# LPC122x register map
File version: 2
Registers are 32-bit, read-write, reset 0x0 unless marked. A register's access mark holds for its fields unless they carry their own. Offsets are from the block's base; [hi:lo] are bit positions; {n}, {i} and the like mark numbered series; 'fields as' and 'values as' point back to an identical list.

## UART0 — Product name title=UM10441 Chapter title=LPC122x UART0 with modem control Modification date=2/2/2011 Major revision=0 Minor revision=17
Base 0x40008000
0x00 RBR ro read-modifies — Receiver Buffer Register. Contains the next received character to be read. (DLAB=0)
  [7:0] RBR — The UART Receiver Buffer Register contains the oldest received byte in the UART RX FIFO.
0x00 THR wo (alternate view of RBR) — Transmit Holding Register. The next character to be transmitted is written here. (DLAB=0)
  [7:0] THR — Writing to the UART Transmit Holding Register causes the data to be stored in the UART transmit FIFO. The byte will be sent when it reaches the bottom of the FIFO and the transmitter is available.
0x00 DLL reset 0x1 (alternate view of RBR) — Divisor Latch LSB. Least significant byte of the baud rate divisor value. The full divisor is used to generate a baud rate from the fractional rate divider. (DLAB = 1)
  [7:0] DLLSB — The UART Divisor Latch LSB Register, along with the DLM register, determines the baud rate of the UART.
0x04 DLM — Divisor Latch MSB. Most significant byte of the baud rate divisor value. The full divisor is used to generate a baud rate from the fractional rate divider. (DLAB = 1)
  [7:0] DLMSB — The UART Divisor Latch MSB Register, along with the DLL register, determines the baud rate of the UART.
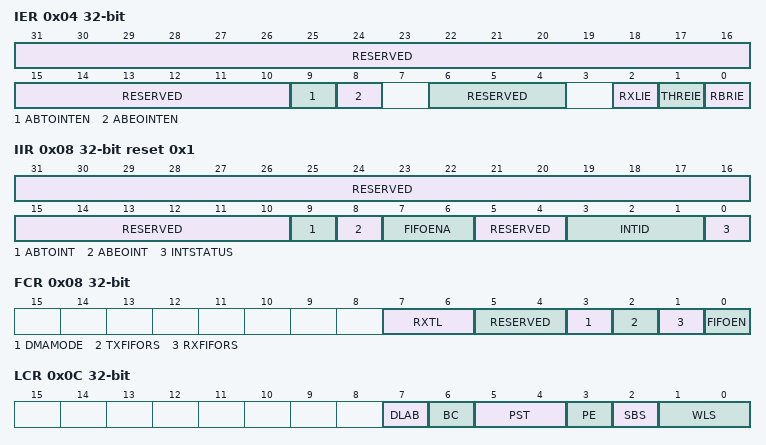
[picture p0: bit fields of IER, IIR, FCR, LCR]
0x04 IER (alternate view of DLM) — Interrupt Enable Register. Contains individual interrupt enable bits for the 7 potential UART interrupts. (DLAB=0)
  [31:10] RESERVED — Reserved, user software should not write ones to reserved bits. The value read from a reserved bit is not defined.
  [9] ABTOINTEN — Enables the auto-baud time-out interrupt.
    0=DISABLE_AUTO_BAUD_TI (Disable auto-baud time-out Interrupt.); 1=ENABLE_AUTO_BAUD_TIM (Enable auto-baud time-out Interrupt.)
  [8] ABEOINTEN — Enables the end of auto-baud interrupt.
    0=DISABLE_END_OF_AUTO_ (Disable end of auto-baud Interrupt.); 1=ENABLE_END_OF_AUTO_B (Enable end of auto-baud Interrupt.)
  [6:4] RESERVED — Reserved, user software should not write ones to reserved bits. The value read from a reserved bit is not defined.
  [2] RXLIE — RX Line Interrupt Enable. Enables the UART RX line status interrupts. The status of this interrupt can be read from LSR[4:1].
    0=DISABLE_THE_RX_LINE_ (Disable the RX line status interrupts.); 1=ENABLE_THE_RX_LINE_S (Enable the RX line status interrupts.)
  [1] THREIE — THRE Interrupt Enable. Enables the THRE interrupt for UART. The status of this interrupt can be read from LSR[5].
    0=DISABLE_THE_THRE_INT (Disable the THRE interrupts.); 1=ENABLE_THE_THRE_INTE (Enable the THRE interrupts.)
  [0] RBRIE — RBR Interrupt Enable. Enables the Receive Data Available interrupt for UART. It also controls the Character Receive Time-out interrupt.
    0=DISABLE_THE_RDA_INTE (Disable the RDA interrupts.); 1=ENABLE_THE_RDA_INTER (Enable the RDA interrupts.)
0x08 IIR ro reset 0x1 — Interrupt ID Register. Identifies which interrupt(s) are pending.
  [31:10] RESERVED — Reserved, user software should not write ones to reserved bits. The value read from a reserved bit is not defined.
  [9] ABTOINT — Auto-baud time-out interrupt. True if auto-baud has timed out and interrupt is enabled.
  [8] ABEOINT — End of auto-baud interrupt. True if auto-baud has finished successfully and interrupt is enabled.
  [7:6] FIFOENA — These bits are equivalent to FCR[0].
  [5:4] RESERVED — Reserved, user software should not write ones to reserved bits. The value read from a reserved bit is not defined.
  [3:1] INTID — Interrupt identification. IER[3:1] identifies an interrupt corresponding to the UART RX FIFO. All other combinations of IER[3:1] not listed below are reserved (100,101,111).
    3=RECEIVE_LINE_S (1 - Receive Line Status (RLS).); 2=RECEIVE_DATA_AV (2a - Receive Data Available (RDA).); 6=CHARACTER_TIME_ (2b - Character Time-out Indicator (CTI).); 1=THRE_INTERRUPT (3 - THRE Interrupt.); 0=MODEM_INTERRUP (4 - Modem interrupt.)
  [0] INTSTATUS — Interrupt status. Note that IIR[0] is active low. The pending interrupt can be determined by evaluating IIR[3:1].
    0=AT_LEAST_ONE_INTERRU (At least one interrupt is pending.); 1=NO_INTERRUPT_IS_PEND (No interrupt is pending.)
0x08 FCR wo (alternate view of IIR) — FIFO Control Register. Controls UART FIFO usage and modes.
  [7:6] RXTL — RX Trigger Level. These two bits determine how many receiver UART FIFO characters must be written before an interrupt is activated.
    0=TRIGGER_LEVEL_0 (Trigger level 0 (1 character or 0x01).); 1=TRIGGER_LEVEL_1 (Trigger level 1 (4 characters or 0x04).); 2=TRIGGER_LEVEL_2 (Trigger level 2 (8 characters or 0x08).); 3=TRIGGER_LEVEL_3 (Trigger level 3 (14 characters or 0x0E).)
  [5:4] RESERVED — Reserved, user software should not write ones to reserved bits. The value read from a reserved bit is not defined.
  [3] DMAMODE — DMA Mode Select. When the FIFO enable bit (bit 0 of this register) is set, this bit selects the DMA mode. See Section 9.5.6.1.
    0=DMA_NOT_USED_; 1=DMA_MODE_ENABLED_
  [2] TXFIFORS — TX FIFO Reset
    0=NO_IMPACT_ON_EITHER_ (No impact on either of UART FIFOs.); 1=CLEAR (Writing a logic 1 to FCR[2] will clear all bytes in UART TX FIFO, reset the pointer logic. This bit is self-clearing.)
  [1] RXFIFORS — RX FIFO Reset
    0=NO_IMPACT_ON_EITHER_ (No impact on either of UART FIFOs.); 1=CLEAR (Writing a logic 1 to FCR[1] will clear all bytes in UART RX FIFO, reset the pointer logic. This bit is self-clearing.)
  [0] FIFOEN — FIFO Enable
    0=DISAB (UART FIFOs are disabled. Must not be used in the application.); 1=ENABLE_F (Active high enable for both UART RX and TX FIFOs and FCR[7:1] access. This bit must be set for proper UART operation. Any transition on this bit will automatically clear the UART FIFOs.)
0x0C LCR — Line Control Register. Contains controls for frame formatting and break generation.
  [7] DLAB — Divisor Latch Access Bit (DLAB)
    0=DISABLE_ACCESS_TO_DI (Disable access to Divisor Latches.); 1=ENABLE_ACCESS_TO_DIV (Enable access to Divisor Latches.)
  [6] BC — Break Control
    0=DISABLE_BREAK_TRANSM (Disable break transmission.); 1=ENABLE_BREAK_TRANSMI (Enable break transmission. Output pin UART TXD is forced to logic 0 when LCR[6] is active high.)
  [5:4] PST — Parity Select
    0=ODD_PARITY_NUMBER_O (Odd parity. Number of 1s in the transmitted character and the attached parity bit will be odd.); 1=EVEN_PARITY_NUMBER_ (Even Parity. Number of 1s in the transmitted character and the attached parity bit will be even.); 2=FORCED_1_STICK_PARIT (Forced 1 stick parity.); 3=FORCED_0_STICK_PARIT (Forced 0 stick parity.)
  [3] PE — Parity Enable
    0=DISABLE_PARITY_GENER (Disable parity generation and checking.); 1=ENABLE_PARITY_GENERA (Enable parity generation and checking.)
  [2] SBS — Stop Bit Select
    0=1_STOP_BIT_; 1=2_STOP_BITS (2 stop bits (1.5 if LCR[1:0]=00).)
  [1:0] WLS — Word Length Select
    {v}={v+5}_BIT_CHARACTER_LENG ({v+5}-bit character length.) (v=0..3)
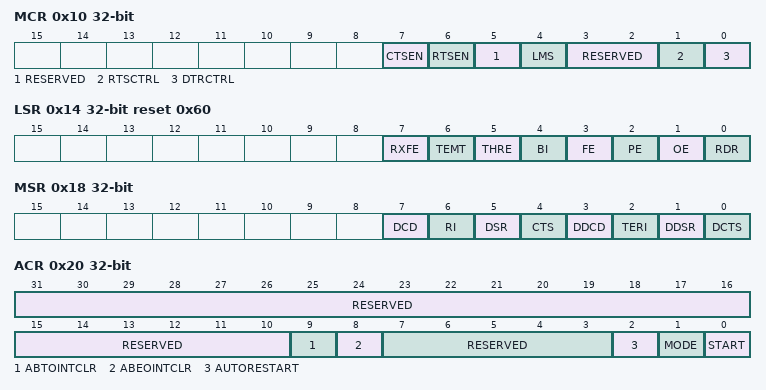
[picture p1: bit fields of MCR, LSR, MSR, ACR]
0x10 MCR — Modem control register
  [7] CTSEN — CTS enable
    0=DISABLE_AUTO_CTS_FLO (Disable auto-cts flow control.); 1=ENABLE_AUTO_CTS_FLOW (Enable auto-cts flow control.)
  [6] RTSEN — RTS enable
    0=DISABLE_AUTO_RTS_FLO (Disable auto-rts flow control.); 1=ENABLE_AUTO_RTS_FLOW (Enable auto-rts flow control.)
  [5] RESERVED — Reserved, user software should not write ones to reserved bits. The value read from a reserved bit is not defined.
  [4] LMS — Loopback Mode Select. The modem loopback mode provides a mechanism to perform diagnostic loopback testing. Serial data from the transmitter is connected internally to serial input of the receiver. Input pin, RXD, has no effect on loopback and output pin, TXD is held in marking state. The DSR, CTS, DCD, and RI pins are ignored. Externally, DTR and RTS are set inactive. Internally, the upper four bits of the MSR are driven by the lower four bits of the MCR. This permits modem status interrupts to be generated in loopback mode by writing the lower four bits of MCR.
    0=DISABLE_MODEM_LOOPBA (Disable modem loopback mode.); 1=ENABLE_MODEM_LOOPBAC (Enable modem loopback mode.)
  [3:2] RESERVED — Reserved, user software should not write ones to reserved bits. The value read from a reserved bit is not defined.
  [1] RTSCTRL — Source for modem output pin RTS. This bit reads as 0 when modem loopback mode is active.
  [0] DTRCTRL — Source for modem output pin DTR. This bit reads as 0 when modem loopback mode is active.
0x14 LSR ro reset 0x60 — Line Status Register. Contains flags for transmit and receive status, including line errors.
  [7] RXFE — Error in RX FIFO. LSR[7] is set when a character with a RX error such as framing error, parity error or break interrupt, is loaded into the RBR. This bit is cleared when the LSR register is read and there are no subsequent errors in the UART FIFO.
    0=RBR_CONTAINS_NO_UART (RBR contains no UART RX errors or FCR[0]=0.); 1=UART_RBR_CONTAINS_AT (UART RBR contains at least one UART RX error.)
  [6] TEMT — Transmitter Empty. TEMT is set when both THR and TSR are empty; TEMT is cleared when either the TSR or the THR contain valid data.
    0=VALID_DATA (THR and/or the TSR contains valid data.); 1=EMPTY (THR and the TSR are empty.)
  [5] THRE — Transmitter Holding Register Empty. THRE is set immediately upon detection of an empty UART THR and is cleared on a THR write.
    0=THR_CONTAINS_VALID_D (THR contains valid data.); 1=THR_IS_EMPTY_
  [4] BI — Break Interrupt. When RXD1 is held in the spacing state (all zeros) for one full character transmission (start, data, parity, stop), a break interrupt occurs. Once the break condition has been detected, the receiver goes idle until RXD1 goes to marking state (all ones). A LSR read clears this status bit. The time of break detection is dependent on FCR[0]. Note: The break interrupt is associated with the character at the top of the UART RBR FIFO.
    0=INACTIVE (Break interrupt status is inactive.); 1=ACTIVE (Break interrupt status is active.)
  [3] FE — Framing Error. When the stop bit of a received character is a logic 0, a framing error occurs. A LSR read clears LSR[3]. The time of the framing error detection is dependent on FCR0. Upon detection of a framing error, the RX will attempt to re-synchronize to the data and assume that the bad stop bit is actually an early start bit. However, it cannot be assumed that the next received byte will be correct even if there is no Framing Error. Note: A framing error is associated with the character at the top of the UART RBR FIFO.
    0=INACTIVE (Framing error status is inactive.); 1=ACTIVE (Framing error status is active.)
  [2] PE — Parity Error. When the parity bit of a received character is in the wrong state, a parity error occurs. A LSR read clears LSR[2]. Time of parity error detection is dependent on FCR[0]. Note: A parity error is associated with the character at the top of the UART RBR FIFO.
    0=INACTIVE (Parity error status is inactive.); 1=ACTIVE (Parity error status is active.)
  [1] OE — Overrun Error. The overrun error condition is set as soon as it occurs. A LSR read clears LSR[1]. LSR[1] is set when UART RSR has a new character assembled and the UART RBR FIFO is full. In this case, the UART RBR FIFO will not be overwritten and the character in the UART RSR will be lost.
    0=INACTIVE (Overrun error status is inactive.); 1=ACTIVE (Overrun error status is active.)
  [0] RDR — Receiver Data Ready:LSR[0] is set when the RBR holds an unread character and is cleared when the UART RBR FIFO is empty.
    0=RBR_IS_EMPTY_; 1=RBR_CONTAINS_VALID_D (RBR contains valid data.)
0x18 MSR ro — Modem status register
  [7] DCD — Data Carrier Detect State. Complement of input DCD. This bit is connected to MCR[3] in modem loopback mode.
  [6] RI — Ring Indicator State. Complement of input RI. This bit is connected to MCR[2] in modem loopback mode.
  [5] DSR — Data Set Ready State. Complement of input signal DSR. This bit is connected to MCR[0] in modem loopback mode.
  [4] CTS — Clear To Send State. Complement of input signal CTS. This bit is connected to MCR[1] in modem loopback mode.
  [3] DDCD — Delta DCD. Set upon state change of input DCD. Cleared on an MSR read.
    0=NO_CHANGE_DETECTED_O (No change detected on modem input, DCD.); 1=STATE_CHANGE_DETECTE (State change detected on modem input, DCD.)
  [2] TERI — Trailing Edge RI. Set upon low to high transition of input RI. Cleared on an MSR read.
    0=NO_CHANGE_DETECTED_O (No change detected on modem input, RI.); 1=LOW_TO_HIGH_TRANSITI (Low-to-high transition detected on RI.)
  [1] DDSR — Delta DSR. Set upon state change of input DSR. Cleared on an MSR read.
    0=NO_CHANGE_DETECTED_O (No change detected on modem input, DSR.); 1=STATE_CHANGE_DETECTE (State change detected on modem input, DSR.)
  [0] DCTS — Delta CTS. Set upon state change of input CTS. Cleared on an MSR read.
    0=NO_CHANGE_DETECTED_O (No change detected on modem input, CTS.); 1=STATE_CHANGE_DETECTE (State change detected on modem input, CTS.)
0x1C SCR — Scratch Pad Register. Eight-bit temporary storage for software.
  [7:0] PAD — A readable, writable byte.
0x20 ACR — Auto-baud Control Register. Contains controls for the auto-baud feature.
  [31:10] RESERVED — Reserved, user software should not write ones to reserved bits. The value read from a reserved bit is not defined.
  [9] ABTOINTCLR — Auto-baud time-out interrupt clear bit (write only accessible).
    0=WRITING_A_0_HAS_NO_I (Writing a 0 has no impact.); 1=CLEAR (Writing a 1 will clear the corresponding interrupt in the IIR.)
  [8] ABEOINTCLR — End of auto-baud interrupt clear bit (write only accessible).
    values as ABTOINTCLR
  [7:3] RESERVED — Reserved, user software should not write ones to reserved bits. The value read from a reserved bit is not defined.
  [2] AUTORESTART — Start mode.
    0=NO_RESTART; 1=RESTART_IN_CASE_OF_T (Restart in case of time-out (counter restarts at next UART RX falling edge))
  [1] MODE — Auto-baud mode select bit.
    0=MODE_0_; 1=MODE_1_
  [0] START — Start bit. This bit is automatically cleared after auto-baud completion.
    0=AUTO_BAUD_STOP_(AUTO (Auto-baud stop (auto-baud is not running).); 1=AUTO_BAUD_START_(AUT (Auto-baud start (auto-baud is running). Auto-baud run bit. This bit is automatically cleared after auto-baud completion.)
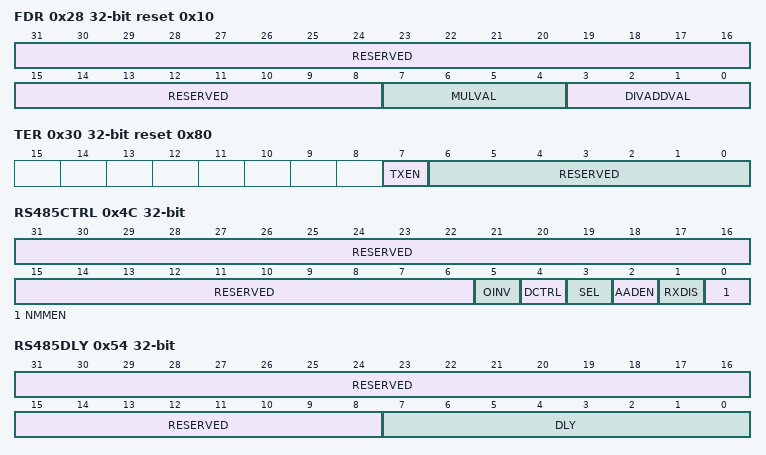
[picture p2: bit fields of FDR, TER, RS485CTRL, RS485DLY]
0x28 FDR reset 0x10 — Fractional Divider Register. Generates a clock input for the baud rate divider.
  [31:8] RESERVED — Reserved, user software should not write ones to reserved bits. The value read from a reserved bit is not defined.
  [7:4] MULVAL — Baud-rate pre-scaler multiplier value. This field must be greater or equal 1 for UARTn to operate properly, regardless of whether the fractional baud-rate generator is used or not.
  [3:0] DIVADDVAL — Baud-rate generation pre-scaler divisor value. If this field is 0, fractional baud-rate generator will not impact the UARTn baudrate.
0x30 TER reset 0x80 — Transmit Enable Register. Turns off UART transmitter for use with software flow control.
  [7] TXEN — When this bit is 1, as it is after a Reset, data written to the THR is output on the TXD pin as soon as any preceding data has been sent. If this bit cleared to 0 while a character is being sent, the transmission of that character is completed, but no further characters are sent until this bit is set again. In other words, a 0 in this bit blocks the transfer of characters from the THR or TX FIFO into the transmit shift register. Software can clear this bit when it detects that the a hardware-handshaking TX-permit signal (CTS) has gone false, or with software handshaking, when it receives an XOFF character (DC3). Software can set this bit again when it detects that the TX-permit signal has gone true, or when it receives an XON (DC1) character.
  [6:0] RESERVED — Reserved, user software should not write ones to reserved bits. The value read from a reserved bit is not defined.
0x4C RS485CTRL — RS-485/EIA-485 Control. Contains controls to configure various aspects of RS-485/EIA-485 modes.
  [31:6] RESERVED — Reserved, user software should not write ones to reserved bits. The value read from a reserved bit is not defined.
  [5] OINV — Polarity control. This bit reverses the polarity of the direction control signal on the RTS (or DTR) pin.
    0=NORMAL (The direction control pin will be driven to logic 0 when the transmitter has data to be sent. It will be driven to logic 1 after the last bit of data has been transmitted.); 1=INVERT (The direction control pin will be driven to logic 1 when the transmitter has data to be sent. It will be driven to logic 0 after the last bit of data has been transmitted.)
  [4] DCTRL — Auto direction control enable.
    0=DISABLE_AUTO_DIRECTI (Disable Auto Direction Control.); 1=ENABLE_AUTO_DIRECTIO (Enable Auto Direction Control.)
  [3] SEL — Select direction control pin
    0=RTS (If direction control is enabled (bit DCTRL = 1), pin RTS is used for direction control.); 1=DTR (If direction control is enabled (bit DCTRL = 1), pin DTR is used for direction control.)
  [2] AADEN — AAD enable.
    0=DISABLED (Auto Address Detect (AAD) is disabled.); 1=ENABLED (Auto Address Detect (AAD) is enabled.)
  [1] RXDIS — Receiver enable.
    0=THE_RECEIVER_IS_ENAB (The receiver is enabled.); 1=THE_RECEIVER_IS_DISA (The receiver is disabled.)
  [0] NMMEN — NMM enable.
    0=DISABLED (RS-485/EIA-485 Normal Multidrop Mode (NMM) is disabled.); 1=ENABLED (RS-485/EIA-485 Normal Multidrop Mode (NMM) is enabled. In this mode, an address is detected when a received byte causes the UART to set the parity error and generate an interrupt.)
0x50 RS485ADRMATCH — RS-485/EIA-485 address match. Contains the address match value for RS-485/EIA-485 mode.
  [7:0] ADRMATCH — Contains the address match value.
0x54 RS485DLY — RS-485/EIA-485 direction control delay.
  [31:8] RESERVED — Reserved, user software should not write ones to reserved bits. The value read from a reserved bit is not defined.
  [7:0] DLY — Contains the direction control (RTS or DTR) delay value. This register works in conjunction with an 8-bit counter.
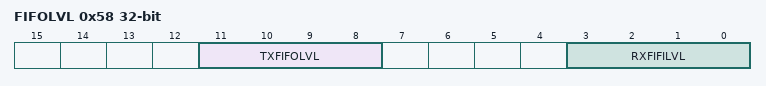
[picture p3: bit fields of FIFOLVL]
0x58 FIFOLVL ro — FIFO Level register. Provides the current fill levels of the transmit and receive FIFOs.
  [11:8] TXFIFOLVL — Reflects the current level of the UART transmitter FIFO. 0 = empty, 0xF = FIFO full.
  [3:0] RXFIFILVL — Reflects the current level of the UART receiver FIFO. 0 = empty, 0xF = FIFO full.
